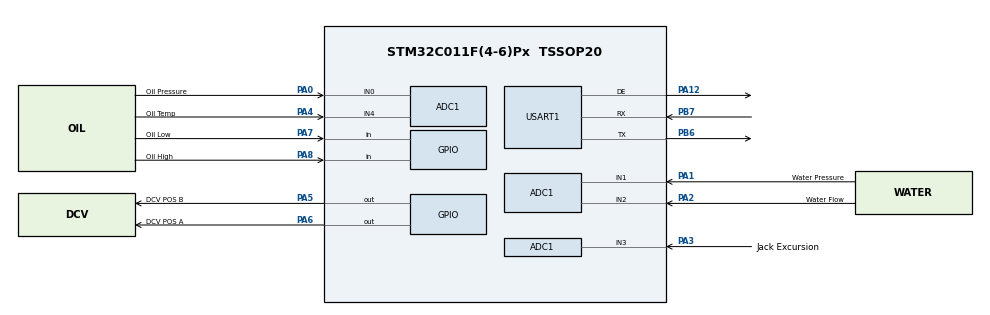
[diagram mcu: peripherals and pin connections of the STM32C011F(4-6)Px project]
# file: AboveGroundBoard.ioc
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ADC1.NbrOfConversion=1
ADC1.NbrOfConversionFlag=0
ADC1.SelectedChannel=ADC_CHANNEL_0|ADC_CHANNEL_1|ADC_CHANNEL_2|ADC_CHANNEL_3|ADC_CHANNEL_4
ADC1.master=1
Mcu.Family=STM32C0
Mcu.Name=STM32C011F(4-6)Px
Mcu.Package=TSSOP20
PA0.GPIO_Label=Oil Pressure
PA0.Mode=IN0
PA0.Signal=ADC1_IN0
PA1.GPIO_Label=Water Pressure
PA1.Mode=IN1
PA1.Signal=ADC1_IN1
PA12\ [PA10].Mode=Hardware Flow Control (RS485)
PA12\ [PA10].Signal=USART1_DE
PA13.Mode=Serial_Wire
PA13.Signal=DEBUG_SWDIO
PA14-BOOT0.Mode=Serial_Wire
PA14-BOOT0.Signal=DEBUG_SWCLK
PA2.GPIO_Label=Water Flow
PA2.Mode=IN2
PA2.Signal=ADC1_IN2
PA3.GPIO_Label=Jack Excursion
PA3.Mode=IN3
PA3.Signal=ADC1_IN3
PA4.GPIO_Label=Oil Temp
PA4.Mode=IN4
PA4.Signal=ADC1_IN4
PA5.GPIO_Label=DCV POS B
PA5.GPIO_ModeDefaultOutputPP=GPIO_MODE_OUTPUT_PP
PA5.Signal=GPIO_Output
PA6.GPIO_Label=DCV POS A
PA6.Signal=GPIO_Output
PA7.GPIO_Label=Oil Low
PA7.Signal=GPIO_Input
PA8.GPIO_Label=Oil High
PA8.GPIO_PuPd=GPIO_PULLDOWN
PA8.Signal=GPIO_Input
PB6.Mode=Asynchronous
PB6.Signal=USART1_TX
PB7.Mode=Asynchronous
PB7.Signal=USART1_RX
PC14-OSCX_IN\ (PC14).Mode=HSE-External-Oscillator-REMAPPED
PC14-OSCX_IN\ (PC14).Signal=RCC_OSCX_IN
PC15-OSCX_OUT\ (PC15).Mode=HSE-External-Oscillator-REMAPPED
PC15-OSCX_OUT\ (PC15).Signal=RCC_OSCX_OUT
ProjectManager.HeapSize=0x200
ProjectManager.StackSize=0x400
ProjectManager.TargetToolchain=STM32CubeIDE
RCC.ADCFreq_Value=12000000
RCC.AHBFreq_Value=12000000
RCC.CortexFreq_Value=12000000
RCC.EXTERNAL_CLOCK_VALUE=12288000
RCC.HCLKFreq_Value=12000000
RCC.HSE_VALUE=8000000
RCC.HSI_VALUE=48000000
RCC.LSE_VALUE=32768
RCC.SYSCLKFreq_VALUE=12000000
USART1.VirtualMode-Asynchronous=VM_ASYNC
USART1.VirtualMode-Hardware\ Flow\ Control\ (RS485)=VM_ASYNC
VP_WWDG_VS_WWDG.Mode=WWDG_Activate
board=custom

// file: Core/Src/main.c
/* USER CODE BEGIN Header */
/**
  ******************************************************************************
  * @file           : main.c
  * @brief          : Main program body
  ******************************************************************************
  * @attention
  *
  * Copyright (c) 2024 STMicroelectronics.
  * All rights reserved.
  *
  * This software is licensed under terms that can be found in the LICENSE file
  * in the root directory of this software component.
  * If no LICENSE file comes with this software, it is provided AS-IS.
  *
  ******************************************************************************
  */
/* USER CODE END Header */
#include "main.h"

/* USER CODE BEGIN Includes */
#include "modbus.h"
/* USER CODE END Includes */

ADC_HandleTypeDef hadc1;

UART_HandleTypeDef huart1;

WWDG_HandleTypeDef hwwdg;

void SystemClock_Config(void);
static void MX_GPIO_Init(void);
static void MX_ADC1_Init(void);
static void MX_USART1_UART_Init(void);
static void MX_WWDG_Init(void);

int main(void)
{

  /* MCU Configuration--------------------------------------------------------*/

  /* Reset of all peripherals, Initializes the Flash interface and the Systick. */
  HAL_Init();

  /* Configure the system clock */
  SystemClock_Config();

  /* Initialize all configured peripherals */
  MX_GPIO_Init();
  MX_ADC1_Init();
  MX_USART1_UART_Init();
  MX_WWDG_Init();
  /* USER CODE BEGIN 2 */
  modbus_setup_rx(12);
  /* USER CODE END 2 */

  /* Infinite loop */
  while (1)
  {
	  if(modbus_rx())
	  {
		  uint16_t buffer[12];
		  for(uint8_t i = 0; i < 12; i++)
		  {
			  buffer[i] = get_response_buffer(i);
		  }
		  modbus_setup_rx(12);
	  }
  }
}

void SystemClock_Config(void)
{
  RCC_OscInitTypeDef RCC_OscInitStruct = {0};
  RCC_ClkInitTypeDef RCC_ClkInitStruct = {0};

  /** Initializes the RCC Oscillators according to the specified parameters
  * in the RCC_OscInitTypeDef structure.
  */
  RCC_OscInitStruct.OscillatorType = RCC_OSCILLATORTYPE_HSI;
  RCC_OscInitStruct.HSIState = RCC_HSI_ON;
  RCC_OscInitStruct.HSIDiv = RCC_HSI_DIV4;
  RCC_OscInitStruct.HSICalibrationValue = RCC_HSICALIBRATION_DEFAULT;
  if (HAL_RCC_OscConfig(&RCC_OscInitStruct) != HAL_OK)
  {
    Error_Handler();
  }

  /** Initializes the CPU, AHB and APB buses clocks
  */
  RCC_ClkInitStruct.ClockType = RCC_CLOCKTYPE_HCLK|RCC_CLOCKTYPE_SYSCLK
                              |RCC_CLOCKTYPE_PCLK1;
  RCC_ClkInitStruct.SYSCLKSource = RCC_SYSCLKSOURCE_HSI;
  RCC_ClkInitStruct.SYSCLKDivider = RCC_SYSCLK_DIV1;
  RCC_ClkInitStruct.AHBCLKDivider = RCC_HCLK_DIV1;
  RCC_ClkInitStruct.APB1CLKDivider = RCC_APB1_DIV1;

  if (HAL_RCC_ClockConfig(&RCC_ClkInitStruct, FLASH_LATENCY_0) != HAL_OK)
  {
    Error_Handler();
  }
}

static void MX_ADC1_Init(void)
{

  ADC_ChannelConfTypeDef sConfig = {0};

  /** Configure the global features of the ADC (Clock, Resolution, Data Alignment and number of conversion)
  */
  hadc1.Instance = ADC1;
  hadc1.Init.ClockPrescaler = ADC_CLOCK_SYNC_PCLK_DIV1;
  hadc1.Init.Resolution = ADC_RESOLUTION_12B;
  hadc1.Init.DataAlign = ADC_DATAALIGN_RIGHT;
  hadc1.Init.ScanConvMode = ADC_SCAN_SEQ_FIXED;
  hadc1.Init.EOCSelection = ADC_EOC_SINGLE_CONV;
  hadc1.Init.LowPowerAutoWait = DISABLE;
  hadc1.Init.LowPowerAutoPowerOff = DISABLE;
  hadc1.Init.ContinuousConvMode = DISABLE;
  hadc1.Init.NbrOfConversion = 1;
  hadc1.Init.DiscontinuousConvMode = DISABLE;
  hadc1.Init.ExternalTrigConv = ADC_SOFTWARE_START;
  hadc1.Init.ExternalTrigConvEdge = ADC_EXTERNALTRIGCONVEDGE_NONE;
  hadc1.Init.DMAContinuousRequests = DISABLE;
  hadc1.Init.Overrun = ADC_OVR_DATA_PRESERVED;
  hadc1.Init.SamplingTimeCommon1 = ADC_SAMPLETIME_1CYCLE_5;
  hadc1.Init.OversamplingMode = DISABLE;
  hadc1.Init.TriggerFrequencyMode = ADC_TRIGGER_FREQ_HIGH;
  if (HAL_ADC_Init(&hadc1) != HAL_OK)
  {
    Error_Handler();
  }

  /** Configure Regular Channel
  */
  sConfig.Channel = ADC_CHANNEL_0;
  sConfig.Rank = ADC_RANK_CHANNEL_NUMBER;
  if (HAL_ADC_ConfigChannel(&hadc1, &sConfig) != HAL_OK)
  {
    Error_Handler();
  }

  /** Configure Regular Channel
  */
  sConfig.Channel = ADC_CHANNEL_1;
  if (HAL_ADC_ConfigChannel(&hadc1, &sConfig) != HAL_OK)
  {
    Error_Handler();
  }

  /** Configure Regular Channel
  */
  sConfig.Channel = ADC_CHANNEL_2;
  if (HAL_ADC_ConfigChannel(&hadc1, &sConfig) != HAL_OK)
  {
    Error_Handler();
  }

  /** Configure Regular Channel
  */
  sConfig.Channel = ADC_CHANNEL_3;
  if (HAL_ADC_ConfigChannel(&hadc1, &sConfig) != HAL_OK)
  {
    Error_Handler();
  }

  /** Configure Regular Channel
  */
  sConfig.Channel = ADC_CHANNEL_4;
  if (HAL_ADC_ConfigChannel(&hadc1, &sConfig) != HAL_OK)
  {
    Error_Handler();
  }

}

static void MX_USART1_UART_Init(void)
{

  huart1.Instance = USART1;
  huart1.Init.BaudRate = 115200;
  huart1.Init.WordLength = UART_WORDLENGTH_8B;
  huart1.Init.StopBits = UART_STOPBITS_1;
  huart1.Init.Parity = UART_PARITY_NONE;
  huart1.Init.Mode = UART_MODE_TX_RX;
  huart1.Init.HwFlowCtl = UART_HWCONTROL_NONE;
  huart1.Init.OverSampling = UART_OVERSAMPLING_16;
  huart1.Init.OneBitSampling = UART_ONE_BIT_SAMPLE_DISABLE;
  huart1.Init.ClockPrescaler = UART_PRESCALER_DIV1;
  huart1.AdvancedInit.AdvFeatureInit = UART_ADVFEATURE_NO_INIT;
  if (HAL_RS485Ex_Init(&huart1, UART_DE_POLARITY_HIGH, 0, 0) != HAL_OK)
  {
    Error_Handler();
  }
  if (HAL_UARTEx_SetTxFifoThreshold(&huart1, UART_TXFIFO_THRESHOLD_1_8) != HAL_OK)
  {
    Error_Handler();
  }
  if (HAL_UARTEx_SetRxFifoThreshold(&huart1, UART_RXFIFO_THRESHOLD_1_8) != HAL_OK)
  {
    Error_Handler();
  }
  if (HAL_UARTEx_DisableFifoMode(&huart1) != HAL_OK)
  {
    Error_Handler();
  }

}

static void MX_WWDG_Init(void)
{

  hwwdg.Instance = WWDG;
  hwwdg.Init.Prescaler = WWDG_PRESCALER_1;
  hwwdg.Init.Window = 64;
  hwwdg.Init.Counter = 64;
  hwwdg.Init.EWIMode = WWDG_EWI_DISABLE;
  if (HAL_WWDG_Init(&hwwdg) != HAL_OK)
  {
    Error_Handler();
  }

}

static void MX_GPIO_Init(void)
{
  GPIO_InitTypeDef GPIO_InitStruct = {0};

  /* GPIO Ports Clock Enable */
  __HAL_RCC_GPIOB_CLK_ENABLE();
  __HAL_RCC_GPIOC_CLK_ENABLE();
  __HAL_RCC_GPIOA_CLK_ENABLE();

  /*Configure GPIO pin Output Level */
  HAL_GPIO_WritePin(GPIOA, DCV_POS_B_Pin|DCV_POS_A_Pin, GPIO_PIN_RESET);

  /*Configure GPIO pins : DCV_POS_B_Pin DCV_POS_A_Pin */
  GPIO_InitStruct.Pin = DCV_POS_B_Pin|DCV_POS_A_Pin;
  GPIO_InitStruct.Mode = GPIO_MODE_OUTPUT_PP;
  GPIO_InitStruct.Pull = GPIO_NOPULL;
  GPIO_InitStruct.Speed = GPIO_SPEED_FREQ_LOW;
  HAL_GPIO_Init(GPIOA, &GPIO_InitStruct);

  /*Configure GPIO pin : Oil_Low_Pin */
  GPIO_InitStruct.Pin = Oil_Low_Pin;
  GPIO_InitStruct.Mode = GPIO_MODE_INPUT;
  GPIO_InitStruct.Pull = GPIO_NOPULL;
  HAL_GPIO_Init(Oil_Low_GPIO_Port, &GPIO_InitStruct);

  /*Configure GPIO pin : Oil_High_Pin */
  GPIO_InitStruct.Pin = Oil_High_Pin;
  GPIO_InitStruct.Mode = GPIO_MODE_INPUT;
  GPIO_InitStruct.Pull = GPIO_PULLDOWN;
  HAL_GPIO_Init(Oil_High_GPIO_Port, &GPIO_InitStruct);

}

void Error_Handler(void)
{
  __disable_irq();
  while (1)
  {
  }
}
